VERSION ""

NS_ :

BS_:

BU_: XXX

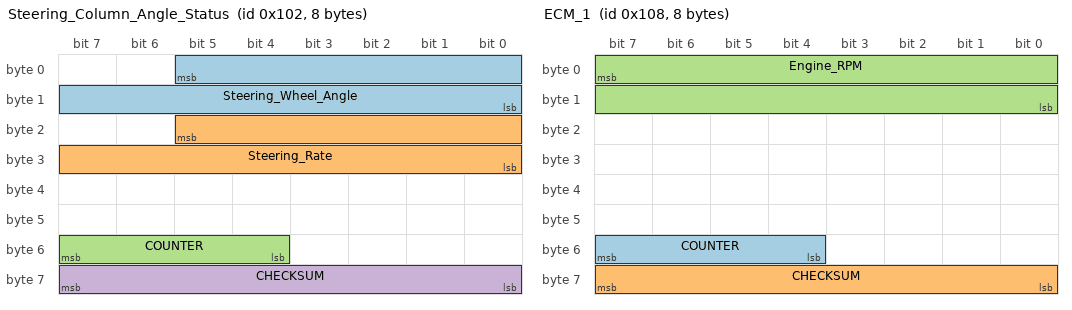
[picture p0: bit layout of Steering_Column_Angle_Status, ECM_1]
BO_ 258 Steering_Column_Angle_Status: 8 XXX
 SG_ Steering_Wheel_Angle : 5|14@0+ (0.5,-2048) [-2048|2047] "Degrees" XXX #2019 Ram 1500
 SG_ Steering_Rate : 21|14@0+ (0.5,-2048) [-2048|2047] "deg/s" XXX #From 2500
 SG_ COUNTER : 55|4@0+ (1,0) [0|15] "" XXX
 SG_ CHECKSUM : 63|8@0+ (1,0) [0|255] "" XXX

BO_ 264 ECM_1: 8 XXX
 SG_ COUNTER : 55|4@0+ (1,0) [0|15] "" XXX
 SG_ CHECKSUM : 63|8@0+ (1,0) [0|255] "" XXX
 SG_ Engine_RPM : 7|16@0+ (1,0) [0|65534] "rpm" XXX

BO_ 280 AXLE_TORQ_ICE: 8 XXX
 SG_ AXLE_TORQ_MAX : 4|13@0+ (.25,-500) [-500|1547.5] "NM" XXX
 SG_ AXLE_TORQ_MIN : 20|13@0+ (.25,-500) [-500|1547.5] "NM" XXX

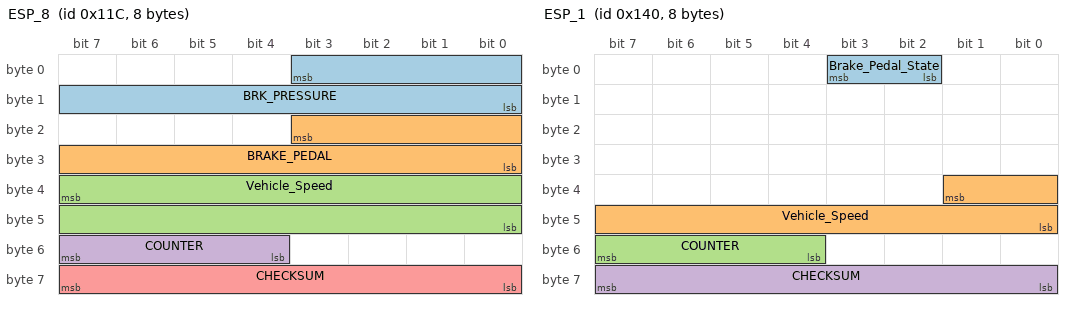
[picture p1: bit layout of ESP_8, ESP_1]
BO_ 284 ESP_8: 8 XXX
 SG_ BRK_PRESSURE : 3|12@0+ (1,0) [0|1] "" XXX
 SG_ BRAKE_PEDAL : 19|12@0+ (1,0) [0|1] "" XXX
 SG_ Vehicle_Speed : 39|16@0+ (0.0078125,0) [0|511.984375] "km/h" XXX
 SG_ COUNTER : 55|4@0+ (1,0) [0|15] "" XXX
 SG_ CHECKSUM : 63|8@0+ (1,0) [0|255] "" XXX

BO_ 320 ESP_1: 8 XXX
 SG_ Brake_Pedal_State : 2|2@1+ (1,0) [0|0] "" XXX
 SG_ Vehicle_Speed : 33|10@0+ (0.5,0) [0|511] "km/h" XXX
 SG_ COUNTER : 55|4@0+ (1,0) [0|15] "" XXX
 SG_ CHECKSUM : 63|8@0+ (1,0) [0|255] "" XXX

BO_ 332 ESP_4: 8 XXX
 SG_ Yaw_Rate : 7|16@0+ (0.01,-327.68) [-327.68|327.66] "deg/s" XXX
 SG_ Acceleration : 32|8@1+ (0.08,-10.24) [-10.24|10.08] "m/s2" XXX

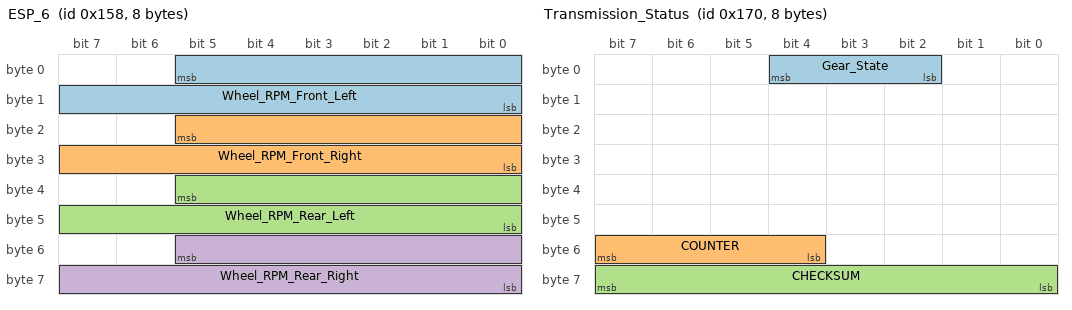
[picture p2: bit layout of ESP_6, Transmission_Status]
BO_ 344 ESP_6: 8 XXX
 SG_ Wheel_RPM_Front_Left : 5|14@0+ (0.5,0) [0|8191] "rpm" XXX
 SG_ Wheel_RPM_Front_Right : 21|14@0+ (0.5,0) [0|8191] "rpm" XXX
 SG_ Wheel_RPM_Rear_Left : 37|14@0+ (0.5,0) [0|8191] "rpm" XXX
 SG_ Wheel_RPM_Rear_Right : 53|14@0+ (0.5,0) [0|8191] "rpm" XXX

BO_ 368 Transmission_Status: 8 XXX
 SG_ Gear_State : 2|3@1+ (1,0) [0|15] "" XXX
 SG_ COUNTER : 55|4@0+ (1,0) [0|15] "" XXX
 SG_ CHECKSUM : 63|8@0+ (1,0) [0|255] "" XXX

BO_ 464 ORC_1: 8 XXX
 SG_ Driver_Seatbelt_Status : 16|1@0+ (1,0) [0|1] "" XXX

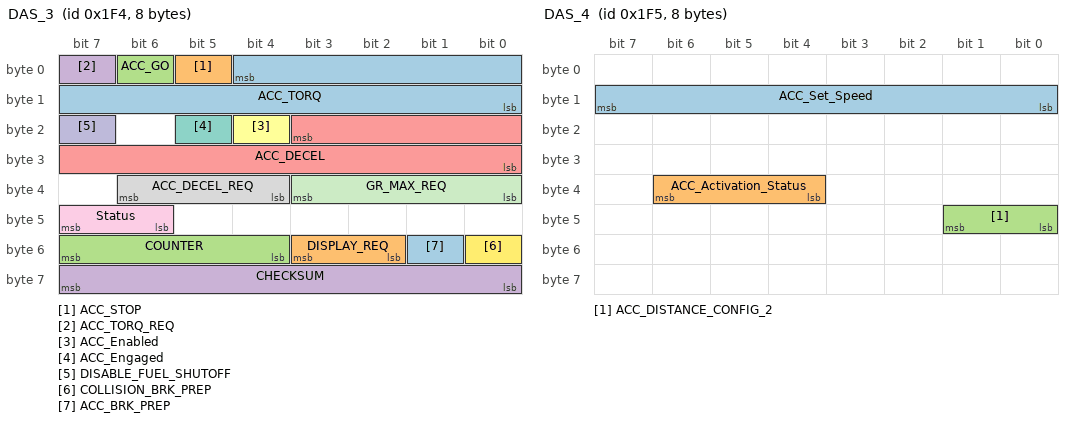
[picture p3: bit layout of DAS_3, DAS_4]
BO_ 500 DAS_3: 8 XXX
 SG_ ACC_TORQ : 4|13@0+ (0.25,-500) [-500|1547.5] "Nm" XXX
 SG_ ACC_STOP : 5|1@1+ (1,0) [0|0] "" XXX
 SG_ ACC_GO : 6|1@1+ (1,0) [0|0] "" XXX
 SG_ ACC_TORQ_REQ : 7|1@1+ (1,0) [0|0] "" XXX
 SG_ ACC_DECEL : 19|12@0+ (0.004885,-16) [-16|4] "m/s2" XXX
 SG_ ACC_Enabled : 20|1@1+ (1,0) [0|0] "" XXX
 SG_ ACC_Engaged : 21|1@1+ (1,0) [0|0] "" XXX
 SG_ ACC_DECEL_REQ : 36|3@1+ (1,0) [0|0] "" XXX
 SG_ Status : 46|2@1+ (1,0) [0|0] ""  XXX
 SG_ DISABLE_FUEL_SHUTOFF : 23|1@1+ (1,0) [0|0] "" XXX
 SG_ GR_MAX_REQ : 32|4@1+ (1,0) [0|0] "" XXX
 SG_ COLLISION_BRK_PREP : 48|1@1+ (1,0) [0|0] "" XXX
 SG_ ACC_BRK_PREP : 49|1@1+ (1,0) [0|0] "" XXX
 SG_ DISPLAY_REQ : 50|2@1+ (1,0) [0|0] "" XXX
 SG_ COUNTER : 55|4@0+ (1,0) [0|15] "" XXX
 SG_ CHECKSUM : 63|8@0+ (1,0) [0|255] "" XXX

BO_ 501 DAS_4: 8 XXX
 SG_ ACC_Set_Speed : 8|8@1+ (1,0) [0|255] "km/h" XXX
 SG_ ACC_Activation_Status : 36|3@1+ (1,0) [0|0] "" XXX
 SG_ ACC_DISTANCE_CONFIG_2 : 41|2@0+ (1,0) [0|3] "" XXX

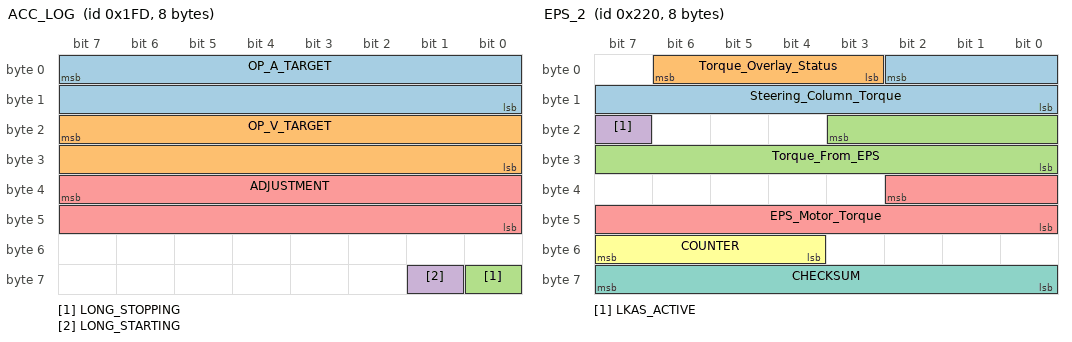
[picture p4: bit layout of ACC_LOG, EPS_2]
BO_ 509 ACC_LOG: 8 XXX
 SG_ OP_A_TARGET : 7|16@0+ (0.00025,-4) [0|65534] "m/s2" XXX
 SG_ OP_V_TARGET : 23|16@0+ (0.00071428571,0) [0|65534] "m/s" XXX
 SG_ LONG_STOPPING : 56|1@0+ (1,0) [0|1] "" XXX
 SG_ LONG_STARTING : 57|1@0+ (1,0) [0|1] "" XXX
 SG_ ADJUSTMENT : 39|16@0+ (1,0) [0|65535] "" XXX

BO_ 544 EPS_2: 8 XXX
 SG_ Steering_Column_Torque : 2|11@0+ (1,-1024) [-1024|1023] "" XXX
 SG_ Torque_Overlay_Status : 6|4@0+ (1,0) [0|15] "" XXX
 SG_ Torque_From_EPS : 19|12@0+ (1,-2048) [-2048|2047] "" XXX
 SG_ LKAS_ACTIVE : 23|1@0+ (1,0) [0|15] "" XXX
 SG_ EPS_Motor_Torque : 34|11@0+ (1,-1024) [-1024|1023] "" XXX
 SG_ COUNTER : 55|4@0+ (1,0) [0|15] "" XXX
 SG_ CHECKSUM : 63|8@0+ (1,0) [0|255] "" XXX

BO_ 559 ECM_5: 8 XXX
 SG_ Accelerator_Position : 0|8@1+ (0.4,0) [0|100] "%" XXX

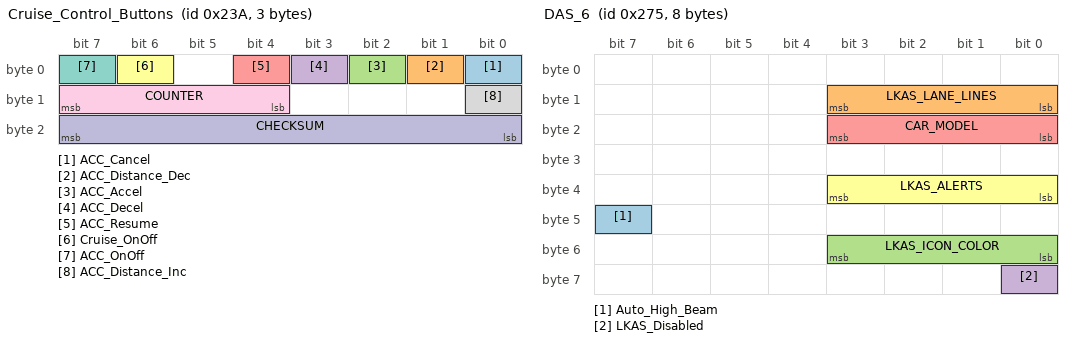
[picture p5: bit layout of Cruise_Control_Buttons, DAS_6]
BO_ 570 Cruise_Control_Buttons: 3 XXX
 SG_ ACC_Cancel : 0|1@1+ (1,0) [0|0] "" XXX
 SG_ ACC_Distance_Dec : 1|1@1+ (1,0) [0|0] "" XXX
 SG_ ACC_Accel : 2|1@1+ (1,0) [0|0] "" XXX
 SG_ ACC_Decel : 3|1@1+ (1,0) [0|0] "" XXX
 SG_ ACC_Resume : 4|1@0+ (1,0) [0|1] "" XXX
 SG_ Cruise_OnOff : 6|1@1+ (1,0) [0|0] "" XXX
 SG_ ACC_OnOff : 7|1@1+ (1,0) [0|0] "" XXX
 SG_ ACC_Distance_Inc : 8|1@1+ (1,0) [0|0] "" XXX
 SG_ COUNTER : 15|4@0+ (1,0) [0|15] "" XXX
 SG_ CHECKSUM : 23|8@0+ (1,0) [0|255] "" XXX

BO_ 629 DAS_6: 8 XXX
 SG_ Auto_High_Beam : 47|1@1+ (1,0) [0|0] "" XXX
 SG_ LKAS_LANE_LINES : 11|4@0+ (1,0) [0|15] "" XXX
 SG_ LKAS_ICON_COLOR : 51|4@0+ (1,0) [0|15] "" XXX
 SG_ LKAS_Disabled : 56|1@1+ (1,0) [0|0] "" XXX
 SG_ CAR_MODEL : 19|4@0+ (1,0) [0|255] "" XXX
 SG_ LKAS_ALERTS : 35|4@0+ (1,0) [0|1] "" XXX

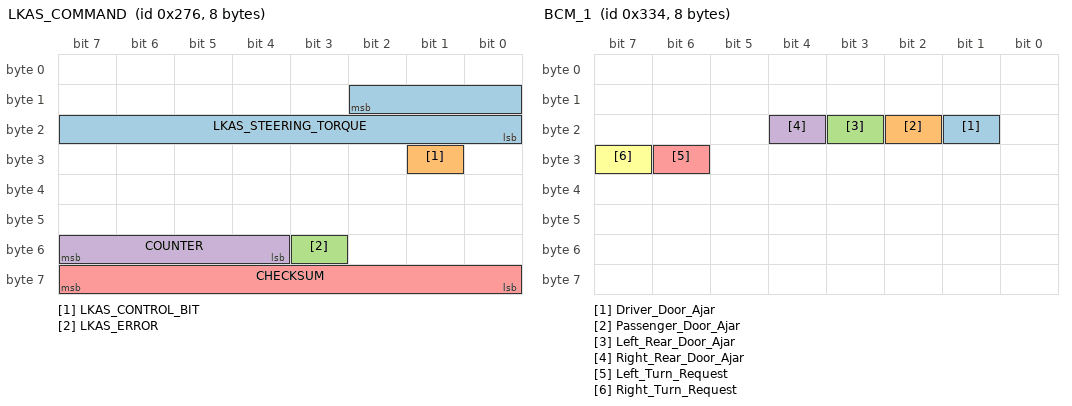
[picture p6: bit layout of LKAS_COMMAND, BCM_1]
BO_ 630 LKAS_COMMAND: 8 XXX
 SG_ LKAS_STEERING_TORQUE : 10|11@0+ (1,-1024) [0|1] "" XXX
 SG_ LKAS_CONTROL_BIT : 25|1@0+ (1,0) [0|1] "" XXX
 SG_ LKAS_ERROR : 51|1@0+ (1,0) [0|1] "" XXX
 SG_ COUNTER : 55|4@0+ (1,0) [0|15] "" XXX
 SG_ CHECKSUM : 63|8@0+ (1,0) [0|255] "" XXX

BO_ 650 Center_Stack_2: 8 XXX
 SG_ LKAS_Button : 57|1@1+ (1,0) [0|0] "" XXX

BO_ 720 BSM_1: 6 XXX
 SG_ Blind_Spot_Monitor_Left : 0|3@1+ (1,0) [0|0] "" XXX
 SG_ Blind_Spot_Monitor_Right : 3|3@1+ (1,0) [0|0] "" XXX

BO_ 792 Steering_Column_Commands: 8 XXX
 SG_ Turn_Signal_Status : 0|2@1+ (1,0) [0|3] "" XXX
 SG_ High_Beam_Lever_Status : 2|2@1+ (1,0) [0|0] "" XXX

BO_ 816 Center_Stack_1: 8 XXX
 SG_ Traction_Button : 54|1@0+ (1,0) [0|1] "" XXX

BO_ 820 BCM_1: 8 XXX
 SG_ Driver_Door_Ajar : 17|1@1+ (1,0) [0|0] "" XXX
 SG_ Passenger_Door_Ajar : 18|1@1+ (1,0) [0|0] "" XXX
 SG_ Left_Rear_Door_Ajar : 19|1@1+ (1,0) [0|0] "" XXX
 SG_ Right_Rear_Door_Ajar : 20|1@1+ (1,0) [0|0] "" XXX
 SG_ Left_Turn_Request : 30|1@1+ (1,0) [0|0] "" XXX
 SG_ Right_Turn_Request : 31|1@1+ (1,0) [0|0] ""  XXX

CM_ SG_ 258 Steering_Wheel_Angle "540 deg total negative values indicate right turn, positive values indicate left turn";
CM_ SG_ 500 ACC_Engaged "SENT BY FORWARD CAMERA 1 = ACTIVE, 3 = ENGAGED, 0 = DISENGAGED/OFF";
CM_ SG_ 630 LKAS_COMMAND "SENT BY FORWARD CAMERA";
CM_ SG_ 630 LKAS_CONTROL_BIT "appears to be the lkas takeover indicator";
CM_ SG_ 629 Auto_High_Beam "1 = HIGH BEAMS OK 0 = HIGH BEAMS OFF ";
CM_ SG_ 629 LKAS_LANE_LINES "9 = LEFT CAUTION, 11 = VERY LEFT CAUTION 10 = RIGHT CAUTION, 14 = VERY RIGHT, 4 = NO LINES DETECTED, 3 = LINES DETECTED, SYSTEM ACTIVE";
CM_ SG_ 464 Driver_Seatbelt_Status "1 unbuckled 0 buckled";
CM_ SG_ 792 High_Beam_Lever_Status "1 is high beam, 0 reg";
VAL_ 368 Gear_State 4 "D" 2 "N" 1 "R" 0 "P" ;
